# LPC176x5x register map
File version: 0.2
CPU: CM3 r0p0, little endian, MPU, no FPU, 5 interrupt priority bits
Registers are 32-bit, read-write, reset 0x0 unless marked. A register's access mark holds for its fields unless they carry their own. Offsets are from the block's base; [hi:lo] are bit positions; {n}, {i} and the like mark numbered series; 'fields as' and 'values as' point back to an identical list.

## SYSCON — System and clock control
Base 0x400FC000
0x00 FLASHCFG reset 0x303A — Flash Accelerator Configuration Register. Controls flash access timing.
  [15:12] FLASHTIM — Flash access time. The value of this field plus 1 gives the number of CPU clocks used for a flash access. Warning: improper setting of this value may result in incorrect operation of the device. Other values are reserved.
    0=1CLK (Flash accesses use 1 CPU clock. Use for up to 20 MHz CPU clock.); 1=2CLK (Flash accesses use 2 CPU clocks. Use for up to 40 MHz CPU clock.); 2=3CLK (Flash accesses use 3 CPU clocks. Use for up to 60 MHz CPU clock.); 3=4CLK (Flash accesses use 4 CPU clocks. Use for up to 80 MHz CPU clock.); 4=5CLK (Flash accesses use 5 CPU clocks. Use for up to 100 MHz CPU clock. Use for up to 120 Mhz for LPC1759 and LPC1769 only.); 5=6CLK (Flash accesses use 6 CPU clocks. This safe setting will work under any conditions.)
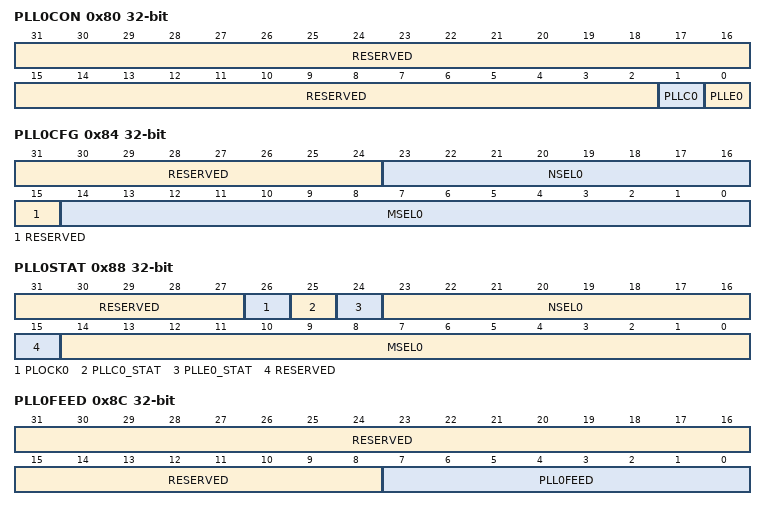
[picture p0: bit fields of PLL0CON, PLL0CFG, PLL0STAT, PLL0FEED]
0x80 PLL0CON — PLL0 Control Register
  [31:2] RESERVED — Reserved, user software should not write ones to reserved bits. The value read from a reserved bit is not defined.
  [1] PLLC0 — PLL0 Connect. Setting PLLC0 to one after PLL0 has been enabled and locked, then followed by a valid PLL0 feed sequence causes PLL0 to become the clock source for the CPU, AHB peripherals, and used to derive the clocks for APB peripherals. The PLL0 output may potentially be used to clock the USB subsystem if the frequency is 48 MHz. See PLL0STAT register.
  [0] PLLE0 — PLL0 Enable. When one, and after a valid PLL0 feed, this bit will activate PLL0 and allow it to lock to the requested frequency. See PLL0STAT register.
0x84 PLL0CFG — PLL0 Configuration Register
  [31:24] RESERVED — Reserved, user software should not write ones to reserved bits. The value read from a reserved bit is not defined.
  [23:16] NSEL0 — PLL0 Pre-Divider value. Supplies the value N in PLL0 frequency calculations. The value stored here is N - 1. Supported values for N are 1 through 32.
  [15] RESERVED — Reserved, user software should not write ones to reserved bits. The value read from a reserved bit is not defined.
  [14:0] MSEL0 — PLL0 Multiplier value. Supplies the value M in PLL0 frequency calculations. The value stored here is M - 1. Note: Not all values of M are needed, and therefore some are not supported by hardware.
0x88 PLL0STAT ro — PLL0 Status Register
  [31:27] RESERVED — Reserved, user software should not write ones to reserved bits. The value read from a reserved bit is not defined.
  [26] PLOCK0 — Reflects the PLL0 Lock status. When zero, PLL0 is not locked. When one, PLL0 is locked onto the requested frequency. See text for details.
  [25] PLLC0_STAT — Read-back for the PLL0 Connect bit. This bit reflects the state of the PLLC0 bit in PLL0CON after a valid PLL0 feed. When PLLC0 and PLLE0 are both one, PLL0 is connected as the clock source for the CPU. When either PLLC0 or PLLE0 is zero, PLL0 is bypassed. This bit is automatically cleared when Power-down mode is entered.
  [24] PLLE0_STAT — Read-back for the PLL0 Enable bit. This bit reflects the state of the PLEC0 bit in PLL0CON after a valid PLL0 feed. When one, PLL0 is currently enabled. When zero, PLL0 is turned off. This bit is automatically cleared when Power-down mode is entered.
  [23:16] NSEL0 — Read-back for the PLL0 Pre-Divider value. This is the value currently used by PLL0, and is one less than the actual divider.
  [15] RESERVED — Reserved, user software should not write ones to reserved bits. The value read from a reserved bit is not defined.
  [14:0] MSEL0 — Read-back for the PLL0 Multiplier value. This is the value currently used by PLL0, and is one less than the actual multiplier.
0x8C PLL0FEED wo reset not defined
  [31:8] RESERVED — Reserved, user software should not write ones to reserved bits. The value read from a reserved bit is not defined.
  [7:0] PLL0FEED — The PLL0 feed sequence must be written to this register in order for PLL0 configuration and control register changes to take effect.
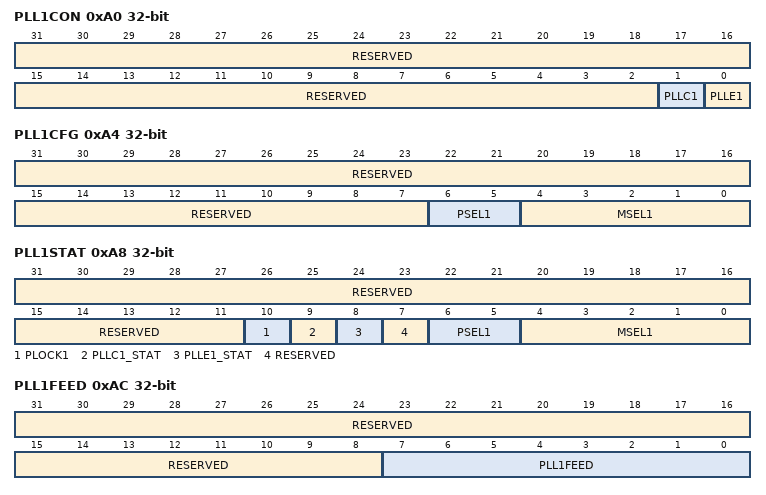
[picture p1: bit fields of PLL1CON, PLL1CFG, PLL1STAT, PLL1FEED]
0xA0 PLL1CON — PLL1 Control Register
  [31:2] RESERVED — Reserved, user software should not write ones to reserved bits. The value read from a reserved bit is not defined.
  [1] PLLC1 — PLL1 Connect. Setting PLLC to one after PLL1 has been enabled and locked, then followed by a valid PLL1 feed sequence causes PLL1 to become the clock source for the USB subsystem via the USB clock divider. See PLL1STAT register.
  [0] PLLE1 — PLL1 Enable. When one, and after a valid PLL1 feed, this bit will activate PLL1 and allow it to lock to the requested frequency.
0xA4 PLL1CFG — PLL1 Configuration Register
  [31:7] RESERVED — Reserved, user software should not write ones to reserved bits. The value read from a reserved bit is not defined.
  [6:5] PSEL1 — PLL1 Divider value. Supplies the value P in the PLL1 frequency calculations.
  [4:0] MSEL1 — PLL1 Multiplier value. Supplies the value M in the PLL1 frequency calculations.
0xA8 PLL1STAT ro — PLL1 Status Register
  [31:11] RESERVED — Reserved, user software should not write ones to reserved bits. The value read from a reserved bit is not defined.
  [10] PLOCK1 — Reflects the PLL1 Lock status. When zero, PLL1 is not locked. When one, PLL1 is locked onto the requested frequency.
  [9] PLLC1_STAT — Read-back for the PLL1 Connect bit. When PLLC and PLLE are both one, PLL1 is connected as the clock source for the microcontroller. When either PLLC or PLLE is zero, PLL1 is bypassed and the oscillator clock is used directly by the microcontroller. This bit is automatically cleared when Power-down mode is activated.
  [8] PLLE1_STAT — Read-back for the PLL1 Enable bit. When one, PLL1 is currently activated. When zero, PLL1 is turned off. This bit is automatically cleared when Power-down mode is activated.
  [7] RESERVED — Reserved, user software should not write ones to reserved bits. The value read from a reserved bit is not defined.
  [6:5] PSEL1 — Read-back for the PLL1 Divider value. This is the value currently used by PLL1.
  [4:0] MSEL1 — Read-back for the PLL1 Multiplier value. This is the value currently used by PLL1.
0xAC PLL1FEED wo reset not defined
  [31:8] RESERVED — Reserved, user software should not write ones to reserved bits. The value read from a reserved bit is not defined.
  [7:0] PLL1FEED — The PLL1 feed sequence must be written to this register in order for PLL1 configuration and control register changes to take effect.
0xC0 PCON — Power Control Register
  [31:12] RESERVED — Reserved, user software should not write ones to reserved bits. The value read from a reserved bit is not defined.
  [11] DPDFLAG — Deep Power-down entry flag. Set when the Deep Power-down mode is successfully entered. Cleared by software writing a one to this bit.
  [10] PDFLAG — Power-down entry flag. Set when the Power-down mode is successfully entered. Cleared by software writing a one to this bit.
  [9] DSFLAG — Deep Sleep entry flag. Set when the Deep Sleep mode is successfully entered. Cleared by software writing a one to this bit.
  [8] SMFLAG — Sleep Mode entry flag. Set when the Sleep mode is successfully entered. Cleared by software writing a one to this bit.
  [4] BORD — Brown-Out Reset Disable. When BORD is 1, the BOD will not reset the device when the VDD(REG)(3V3) voltage dips goes below the BOD reset trip level. The Brown-Out interrupt is not affected. When BORD is 0, the BOD reset is enabled.
  [3] BOGD — Brown-Out Global Disable. When BOGD is 1, the Brown-Out Detect circuitry is fully disabled at all times, and does not consume power. When 0, the Brown-Out Detect circuitry is enabled. See the System Control Block chapter for details of Brown-Out detection. Note: the Brown-Out Reset Disable (BORD, in this register) and the Brown-Out Interrupt (xx) must be disabled when software changes the value of this bit.
  [7:3] RESERVED — Reserved, user software should not write ones to reserved bits. The value read from a reserved bit is not defined.
  [2] BODRPM — Brown-Out Reduced Power Mode. When BODRPM is 1, the Brown-Out Detect circuitry will be turned off when chip Power-down mode or Deep Sleep mode is entered, resulting in a further reduction in power usage. However, the possibility of using Brown-Out Detect as a wake-up source from the reduced power mode will be lost. When 0, the Brown-Out Detect function remains active during Power-down and Deep Sleep modes. See the System Control Block chapter for details of Brown-Out detection.
  [1] PM1 — Power mode control bit 1. This bit controls entry to the Deep Power-down mode.
  [0] PM0 — Power mode control bit 0. This bit controls entry to the Power-down mode.
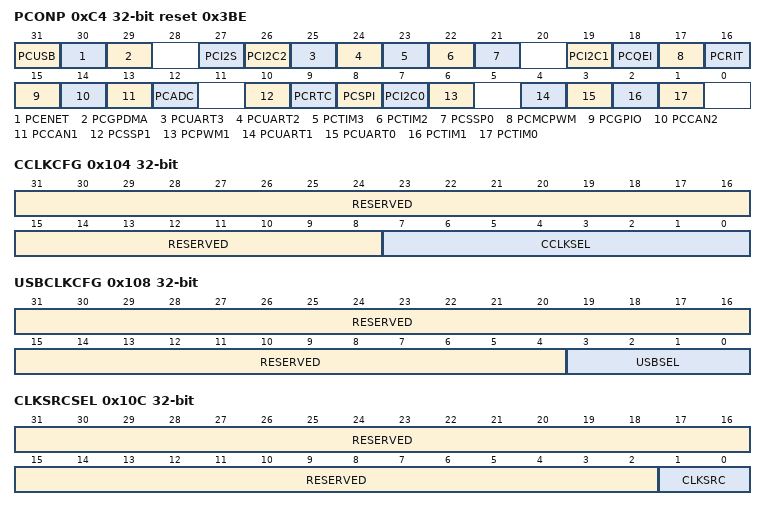
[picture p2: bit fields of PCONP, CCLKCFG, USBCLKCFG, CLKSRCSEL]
0xC4 PCONP reset 0x3BE — Power Control for Peripherals Register
  [31] PCUSB — USB interface power/clock control bit.
  [30] PCENET — Ethernet block power/clock control bit.
  [29] PCGPDMA — GPDMA function power/clock control bit.
  [27] PCI2S — I2S interface power/clock control bit.
  [26] PCI2C2 — I2C interface 2 power/clock control bit.
  [25] PCUART3 — UART 3 power/clock control bit.
  [24] PCUART2 — UART 2 power/clock control bit.
  [23] PCTIM3 — Timer 3 power/clock control bit.
  [22] PCTIM2 — Timer 2 power/clock control bit.
  [21] PCSSP0 — The SSP0 interface power/clock control bit.
  [19] PCI2C1 — The I2C1 interface power/clock control bit.
  [18] PCQEI — Quadrature Encoder Interface power/clock control bit.
  [17] PCMCPWM — Motor Control PWM
  [16] PCRIT — Repetitive Interrupt Timer power/clock control bit.
  [15] PCGPIO — Power/clock control bit for IOCON, GPIO, and GPIO interrupts.
  [14] PCCAN2 — CAN Controller 2 power/clock control bit.
  [13] PCCAN1 — CAN Controller 1 power/clock control bit.
  [12] PCADC — A/D converter (ADC) power/clock control bit. Note: Clear the PDN bit in the AD0CR before clearing this bit, and set this bit before setting PDN.
  [10] PCSSP1 — The SSP 1 interface power/clock control bit.
  [9] PCRTC — The RTC power/clock control bit.
  [8] PCSPI — The SPI interface power/clock control bit.
  [7] PCI2C0 — The I2C0 interface power/clock control bit.
  [6] PCPWM1 — PWM1 power/clock control bit.
  [4] PCUART1 — UART1 power/clock control bit.
  [3] PCUART0 — UART0 power/clock control bit.
  [2] PCTIM1 — Timer/Counter 1 power/clock control bit.
  [1] PCTIM0 — Timer/Counter 0 power/clock control bit.
0x104 CCLKCFG — CPU Clock Configuration Register
  [31:8] RESERVED — Reserved, user software should not write ones to reserved bits. The value read from a reserved bit is not defined.
  [7:0] CCLKSEL — Selects the divide value for creating the CPU clock (CCLK) from the PLL0 output. 0 = pllclk is divided by 1 to produce the CPU clock. This setting is not allowed when the PLL0 is connected, because the rate would always be greater than the maximum allowed CPU clock. 1 = pllclk is divided by 2 to produce the CPU clock. This setting is not allowed when the PLL0 is connected, because the rate would always be greater than the maximum allowed CPU clock. 2 = pllclk is divided by 3 to produce the CPU clock. 3 = pllclk is divided by 4 to produce the CPU clock. ... 255 = pllclk is divided by 256 to produce the CPU clock.
0x108 USBCLKCFG — USB Clock Configuration Register
  [31:4] RESERVED — Reserved, user software should not write ones to reserved bits. The value read from a reserved bit is not defined.
  [3:0] USBSEL — Selects the divide value for creating the USB clock from the PLL0 output. Only the values shown below can produce even number multiples of 48 MHz from the PLL0 output. Warning: Improper setting of this value will result in incorrect operation of the USB interface. 5 = PLL0 output is divided by 6. PLL0 output must be 288 MHz. 7 = PLL0 output is divided by 8. PLL0 output must be 384 MHz. 9 = PLL0 output is divided by 10. PLL0 output must be 480 MHz.
0x10C CLKSRCSEL — Clock Source Select Register
  [31:2] RESERVED — Reserved, user software should not write ones to reserved bits. The value read from a reserved bit is not defined.
  [1:0] CLKSRC — Selects the clock source for PLL0 as follows. Warning: Improper setting of this value, or an incorrect sequence of changing this value may result in incorrect operation of the device.
    0=SELECTS_THE_INTERNAL (Selects the Internal RC oscillator as the PLL0 clock source (default).); 1=SELECTS_THE_MAIN_OSC (Selects the main oscillator as the PLL0 clock source. Select the main oscillator as PLL0 clock source if the PLL0 clock output is used for USB or for CAN with baudrates > 100 kBit/s.); 2=SELECTS_THE_RTC_OSCI (Selects the RTC oscillator as the PLL0 clock source.)
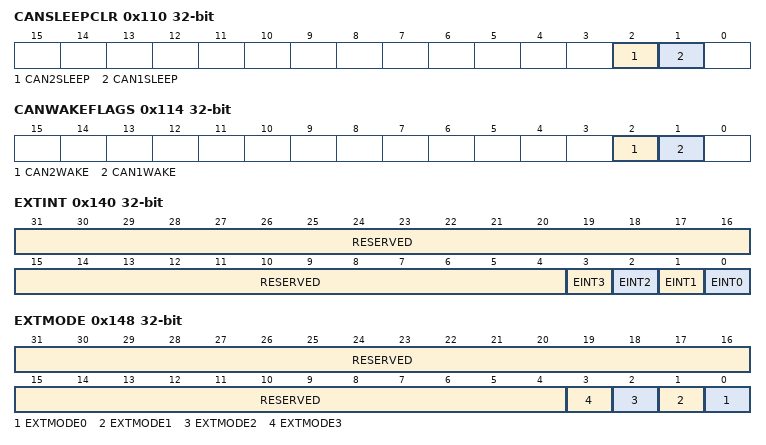
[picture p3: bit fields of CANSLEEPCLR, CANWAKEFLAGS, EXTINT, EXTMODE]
0x110 CANSLEEPCLR — Allows clearing the current CAN channel sleep state as well as reading that state.
  [2] CAN2SLEEP — Sleep status and control for CAN channel 2. Read: when 1, indicates that CAN channel 2 is in the sleep mode. Write: writing a 1 causes clocks to be restored to CAN channel 2.
  [1] CAN1SLEEP — Sleep status and control for CAN channel 1. Read: when 1, indicates that CAN channel 1 is in the sleep mode. Write: writing a 1 causes clocks to be restored to CAN channel 1.
0x114 CANWAKEFLAGS — Allows reading the wake-up state of the CAN channels.
  [2] CAN2WAKE — Wake-up status for CAN channel 2. Read: when 1, indicates that a falling edge has occurred on the receive data line of CAN channel 2. Write: writing a 1 clears this bit.
  [1] CAN1WAKE — Wake-up status for CAN channel 1. Read: when 1, indicates that a falling edge has occurred on the receive data line of CAN channel 1. Write: writing a 1 clears this bit.
0x140 EXTINT — External Interrupt Flag Register
  [31:4] RESERVED — Reserved, user software should not write ones to reserved bits. The value read from a reserved bit is not defined.
  [n] EINT{n} (n=0..3) — In level-sensitive mode, this bit is set if the EINT{n} function is selected for its pin, and the pin is in its active state. In edge-sensitive mode, this bit is set if the EINT{n} function is selected for its pin, and the selected edge occurs on the pin. This bit is cleared by writing a one to it, except in level sensitive mode when the pin is in its active state.
0x148 EXTMODE — External Interrupt Mode register
  [31:4] RESERVED — Reserved, user software should not write ones to reserved bits. The value read from a reserved bit is not defined.
  [n] EXTMODE{n} (n=0..3) — External interrupt {n} EINT{n} mode.
    0=LEVEL_SENSITIVE (Level-sensitive. Level-sensitivity is selected for EINT{n}.); 1=EDGE_SENSITIVE (Edge-sensitive. EINT{n} is edge sensitive.)
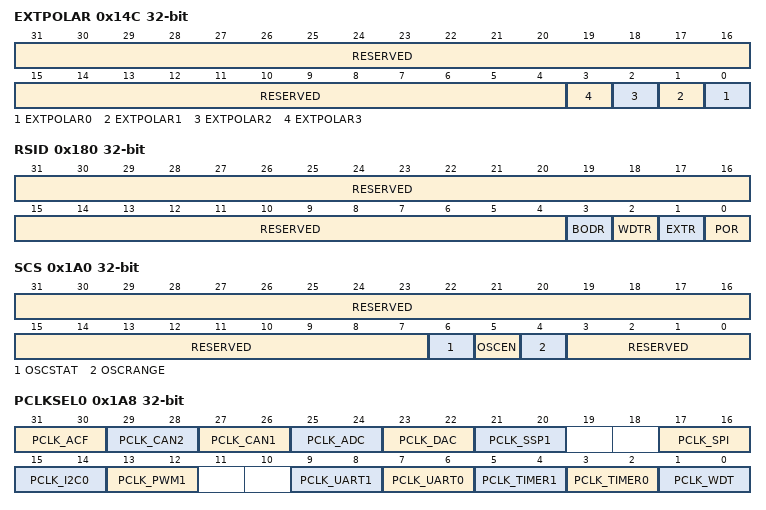
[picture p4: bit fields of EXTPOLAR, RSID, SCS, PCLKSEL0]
0x14C EXTPOLAR — External Interrupt Polarity Register
  [31:4] RESERVED — Reserved, user software should not write ones to reserved bits. The value read from a reserved bit is not defined.
  [n] EXTPOLAR{n} (n=0..3) — External interrupt {n} EINT{n} polarity.
    0=FALLING_EDGE (Falling edge. EINT{n} is low-active or falling-edge sensitive (depending on EXTMODE{n}).); 1=RISING_EDGE (Rising edge. EINT{n} is high-active or rising-edge sensitive (depending on EXTMODE{n}).)
0x180 RSID reset not defined — Reset Source Identification Register
  [31:4] RESERVED — Reserved, user software should not write ones to reserved bits. The value read from a reserved bit is not defined.
  [3] BODR — This bit is set when the VDD(REG)(3V3) voltage reaches a level below the BOD reset trip level (typically 1.85 V under nominal room temperature conditions). If the VDD(REG)(3V3) voltage dips from the normal operating range to below the BOD reset trip level and recovers, the BODR bit will be set to 1. If the VDD(REG)(3V3) voltage dips from the normal operating range to below the BOD reset trip level and continues to decline to the level at which POR is asserted (nominally 1 V), the BODR bit is cleared. If the VDD(REG)(3V3) voltage rises continuously from below 1 V to a level above the BOD reset trip level, the BODR will be set to 1. This bit is cleared only by software or POR. Note: Only in the case where a reset occurs and the POR = 0, the BODR bit indicates if the VDD(REG)(3V3) voltage was below the BOD reset trip level or not.
  [2] WDTR — This bit is set when the Watchdog Timer times out and the WDTRESET bit in the Watchdog Mode Register is 1. This bit is cleared only by software or POR.
  [1] EXTR — Assertion of the RESET signal sets this bit. This bit is cleared only by software or POR.
  [0] POR — Assertion of the POR signal sets this bit, and clears all of the other bits in this register. But if another Reset signal (e.g., External Reset) remains asserted after the POR signal is negated, then its bit is set. This bit is not affected by any of the other sources of Reset.
0x1A0 SCS — System control and status
  [31:7] RESERVED — Reserved. User software should not write ones to reserved bits. The value read from a reserved bit is not defined.
  [6] OSCSTAT — Main oscillator status.
    0=NOT_READY (Not ready. The main oscillator is not ready to be used as a clock source.); 1=READY (Ready. The main oscillator is ready to be used as a clock source. The main oscillator must be enabled via the OSCEN bit.)
  [5] OSCEN — Main oscillator enable.
    0=DISABLED (Disabled. The main oscillator is disabled.); 1=ENABLED (Enabled.The main oscillator is enabled, and will start up if the correct external circuitry is connected to the XTAL1 and XTAL2 pins.)
  [4] OSCRANGE — Main oscillator range select.
    0=LOW (Low. The frequency range of the main oscillator is 1 MHz to 20 MHz.); 1=HIGH (High. The frequency range of the main oscillator is 15 MHz to 25 MHz.)
  [3:0] RESERVED — Reserved. User software should not write ones to reserved bits. The value read from a reserved bit is not defined.
0x1A8 PCLKSEL0 — Peripheral Clock Selection register 0.
  [31:30] PCLK_ACF — Peripheral clock selection for CAN acceptance filtering.PCLK_CAN1 and PCLK_CAN2 must have the same PCLK divide value when the CAN function is used.
    0=CCLK_DIV_4 (CCLK div 4. PCLK_peripheral = CCLK/4); 1=CCLK (CCLK. PCLK_peripheral = CCLK); 2=CCLK_DIV_2 (CCLK div 2. PCLK_peripheral = CCLK/2); 3=CCLK_DIV_6 (CCLK div 6. PCLK_peripheral = CCLK/6)
  [29:28] PCLK_CAN2 — Peripheral clock selection for CAN2.PCLK_CAN1 and PCLK_CAN2 must have the same PCLK divide value when the CAN function is used.
    0=CCLK_DIV_4 (CCLK div 4. PCLK_peripheral = CCLK/4); 1=CCLK (CCLK. PCLK_peripheral = CCLK); 2=CCLK_DIV_2 (CCLK div 2. PCLK_peripheral = CCLK/2); 3=CCLK_DIV_6 (CCLK div 6. PCLK_peripheral = CCLK/6,)
  [27:26] PCLK_CAN1 — Peripheral clock selection for CAN1.PCLK_CAN1 and PCLK_CAN2 must have the same PCLK divide value when the CAN function is used.
    0=CCLK_DIV_4 (CCLK div 4. PCLK_peripheral = CCLK/4); 1=CCLK (CCLK. PCLK_peripheral = CCLK); 2=CCLK_DIV_2 (CCLK div 2. PCLK_peripheral = CCLK/2); 3=CCLK_DIV_6 (CCLK div 6. PCLK_peripheral = CCLK/6.)
  [25:24] PCLK_ADC — Peripheral clock selection for ADC.
    0=CCLK_DIV_4 (CCLK div 4. PCLK_peripheral = CCLK/4); 1=CCLK (CCLK. PCLK_peripheral = CCLK); 2=CCLK_DIV_2 (CCLK div 2. PCLK_peripheral = CCLK/2); 3=CCLK_DIV_8 (CCLK div 8. PCLK_peripheral = CCLK/8)
  [23:22] PCLK_DAC — Peripheral clock selection for DAC.
    values as PCLK_ADC
  [21:20] PCLK_SSP1 — Peripheral clock selection for SSP1.
    values as PCLK_ADC
  [17:16] PCLK_SPI — Peripheral clock selection for SPI.
    values as PCLK_ADC
  [15:14] PCLK_I2C0 — Peripheral clock selection for I2C0.
    values as PCLK_ADC
  [13:12] PCLK_PWM1 — Peripheral clock selection for PWM1.
    values as PCLK_ADC
  [9:8] PCLK_UART1 — Peripheral clock selection for UART1.
    values as PCLK_ADC
  [7:6] PCLK_UART0 — Peripheral clock selection for UART0.
    values as PCLK_ADC
  [5:4] PCLK_TIMER1 — Peripheral clock selection for TIMER1.
    values as PCLK_ADC
  [3:2] PCLK_TIMER0 — Peripheral clock selection for TIMER0.
    values as PCLK_ADC
  [1:0] PCLK_WDT — Peripheral clock selection for WDT.
    values as PCLK_ADC
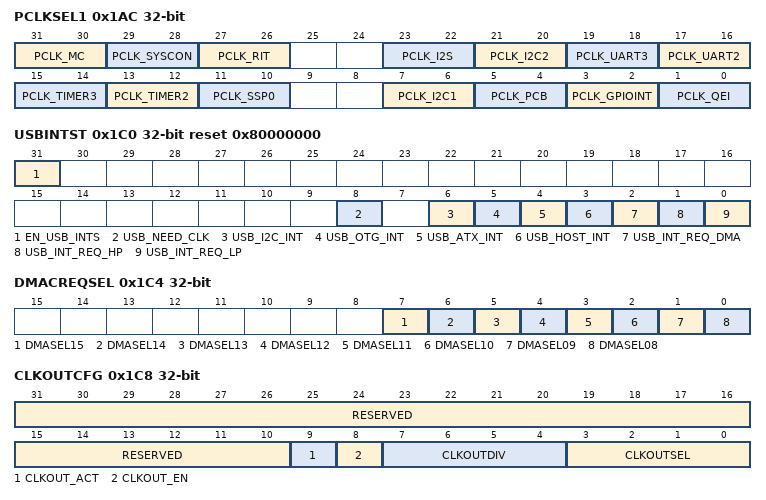
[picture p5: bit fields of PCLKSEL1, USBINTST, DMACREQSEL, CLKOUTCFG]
0x1AC PCLKSEL1 — Peripheral Clock Selection register 1.
  [all] fields
    values as PCLKSEL0.PCLK_ADC
  [31:30] PCLK_MC — Peripheral clock selection for the Motor Control PWM.
  [29:28] PCLK_SYSCON — Peripheral clock selection for the System Control block.
  [27:26] PCLK_RIT — Peripheral clock selection for Repetitive Interrupt Timer.
  [23:22] PCLK_I2S — Peripheral clock selection for I2S.
  [21:20] PCLK_I2C2 — Peripheral clock selection for I2C2.
  [19:18] PCLK_UART3 — Peripheral clock selection for UART3.
  [17:16] PCLK_UART2 — Peripheral clock selection for UART2.
  [15:14] PCLK_TIMER3 — Peripheral clock selection for TIMER3.
  [13:12] PCLK_TIMER2 — Peripheral clock selection for TIMER2.
  [11:10] PCLK_SSP0 — Peripheral clock selection for SSP0.
  [7:6] PCLK_I2C1 — Peripheral clock selection for I2C1.
  [5:4] PCLK_PCB — Peripheral clock selection for the Pin Connect block.
  [3:2] PCLK_GPIOINT — Peripheral clock selection for GPIO interrupts.
  [1:0] PCLK_QEI — Peripheral clock selection for the Quadrature Encoder Interface.
0x1C0 USBINTST reset 0x80000000 — USB Interrupt Status
  [31] EN_USB_INTS — Enable all USB interrupts. When this bit is cleared, the NVIC does not see the ORed output of the USB interrupt lines.
  [8] USB_NEED_CLK — USB need clock indicator. This bit is read-only. This bit is set to 1 when USB activity or a change of state on the USB data pins is detected, and it indicates that a PLL supplied clock of 48 MHz is needed. Once USB_NEED_CLK becomes one, it resets to zero 5 ms after the last packet has been received/sent, or 2 ms after the Suspend Change (SUS_CH) interrupt has occurred. A change of this bit from 0 to 1 can wake up the microcontroller if activity on the USB bus is selected to wake up the part from the Power-down mode (see Section 4.7.9 Wake-up from Reduced Power Modes for details). Also see Section 4.5.8 PLLs and Power-down mode and Section 4.7.10 Power Control for Peripherals register (PCONP - 0x400F C0C4) for considerations about the PLL and invoking the Power-down mode. This bit is read-only.
  [6] USB_I2C_INT — I2C module interrupt line status. This bit is read-only.
  [5] USB_OTG_INT — OTG interrupt line status. This bit is read-only.
  [4] USB_ATX_INT — External ATX interrupt line status. This bit is read-only.
  [3] USB_HOST_INT — USB host interrupt line status. This bit is read-only.
  [2] USB_INT_REQ_DMA — DMA interrupt line status. This bit is read-only.
  [1] USB_INT_REQ_HP — High priority interrupt line status. This bit is read-only.
  [0] USB_INT_REQ_LP — Low priority interrupt line status. This bit is read-only.
0x1C4 DMACREQSEL — Selects between alternative requests on DMA channels 0 through 7 and 10 through 15
  [7] DMASEL15 — Selects the DMA request for GPDMA input 15: 0 - uart3 rx is selected. 1 - I2S channel 1 is selected.
  [6] DMASEL14 — Selects the DMA request for GPDMA input 14: 0 - uart3 tx is selected. 1 - I2S channel 0 is selected.
  [5] DMASEL13 — Selects the DMA request for GPDMA input 13: 0 - uart2 rx is selected. 1 - Timer 2 match 1 is selected.
  [4] DMASEL12 — Selects the DMA request for GPDMA input 12: 0 - uart2 tx is selected. 1 - Timer 2 match 0 is selected.
  [3] DMASEL11 — Selects the DMA request for GPDMA input 11: 0 - uart1 rx is selected. 1 - Timer 1 match 1 is selected.
  [2] DMASEL10 — Selects the DMA request for GPDMA input 10: 0 - uart1 tx is selected. 1 - Timer 1 match 0 is selected.
  [1] DMASEL09 — Selects the DMA request for GPDMA input 9: 0 - uart0 rx 1 - Timer 0 match 1 is selected.
  [0] DMASEL08 — Selects the DMA request for GPDMA input 8: 0 - uart0 tx 1 - Timer 0 match 0 is selected.
0x1C8 CLKOUTCFG — Clock Output Configuration Register
  [31:10] RESERVED — Reserved, user software should not write ones to reserved bits. The value read from a reserved bit is not defined.
  [9] CLKOUT_ACT — CLKOUT activity indication. Reads as 1 when CLKOUT is enabled. Read as 0 when CLKOUT has been disabled via the CLKOUT_EN bit and the clock has completed being stopped.
  [8] CLKOUT_EN — CLKOUT enable control, allows switching the CLKOUT source without glitches. Clear to stop CLKOUT on the next falling edge. Set to enable CLKOUT.
  [7:4] CLKOUTDIV — Integer value to divide the output clock by, minus one. 0 = Clock is divided by 1 1 = Clock is divided by 2. 2 = Clock is divided by 3. ... 15 = Clock is divided by 16.
  [3:0] CLKOUTSEL — Selects the clock source for the CLKOUT function. Other values are reserved. Do not use.
    0=SELECTS_THE_CPU_CLOC (Selects the CPU clock as the CLKOUT source.); 1=SELECTS_THE_MAIN_OSC (Selects the main oscillator as the CLKOUT source.); 2=SELECTS_THE_INTERNAL (Selects the Internal RC oscillator as the CLKOUT source.); 3=SELECTS_THE_USB_CLOC (Selects the USB clock as the CLKOUT source.); 4=SELECTS_THE_RTC_OSCI (Selects the RTC oscillator as the CLKOUT source.)
